# ATSAM4SD16B device description
Architecture: CORTEX-M4; Family: SAM4; Series: SAM4S
Registers are 32-bit, read-write, no defined reset value unless marked. A register's access mark holds for its fields unless they carry their own. Offsets are from the block's base; [hi:lo] are bit positions; {n}, {i} and the like mark numbered series.

## GPBR — General Purpose Backup Registers
Instances: GPBR 0x400E1490
{0x0+4i} SYS_GPBR{i} (i=0..7) — General Purpose Backup Register {i}
  [31:0] GPBR_VALUE — Value of GPBR x

## MATRIX — AHB Bus Matrix
Instances: MATRIX 0x400E0200
{0x0+4i} MATRIX_MCFG{i} (i=0..3) — Master Configuration Register {i}
  [2:0] ULBT — Undefined Length Burst Type
    0=INFINITE (No predicted end of burst is generated and therefore INCR bursts coming from this master cannot be broken.); 1=SINGLE (The undefined length burst is treated as a succession of single access allowing rearbitration at each beat of the INCR burst.); 2=FOUR_BEAT (The undefined length burst is split into a 4-beat bursts allowing rearbitration at each 4-beat burst end.); 3=EIGHT_BEAT (The undefined length burst is split into 8-beat bursts allowing rearbitration at each 8-beat burst end.); 4=SIXTEEN_BEAT (The undefined length burst is split into 16-beat bursts allowing rearbitration at each 16-beat burst end.)
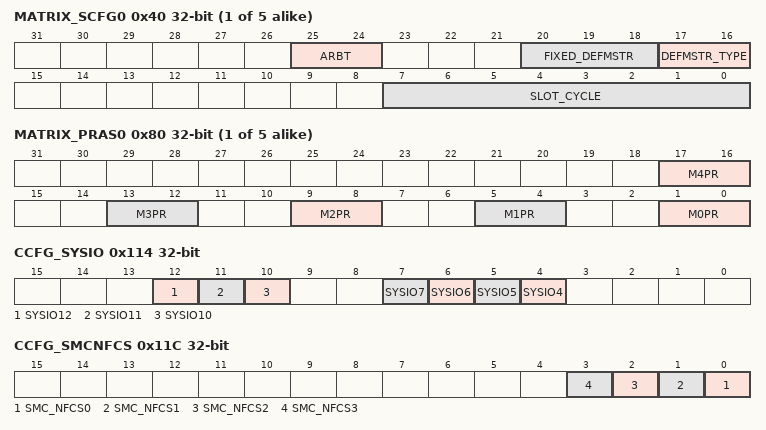
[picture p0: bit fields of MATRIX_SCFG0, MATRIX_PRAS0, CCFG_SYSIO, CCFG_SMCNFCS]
{0x40+4i} MATRIX_SCFG{i} (i=0..4) — Slave Configuration Register {i}
  [25:24] ARBT — Arbitration Type
    0=ROUND_ROBIN (Round-robin arbitration); 1=FIXED_PRIORITY (Fixed priority arbitration)
  [20:18] FIXED_DEFMSTR — Fixed Default Master
  [17:16] DEFMSTR_TYPE — Default Master Type
    0=NO_DEFAULT (At the end of current slave access, if no other master request is pending, the slave is disconnected from all masters.This results in having a one cycle latency for the first access of a burst transfer or for a single access.); 1=LAST (At the end of current slave access, if no other master request is pending, the slave stays connected to the last master having accessed it.This results in not having the one cycle latency when the last master tries to access the slave again.); 2=FIXED (At the end of the current slave access, if no other master request is pending, the slave connects to the fixed master the number that has been written in the FIXED_DEFMSTR field.This results in not having the one cycle latency when the fixed master tries to access the slave again.)
  [7:0] SLOT_CYCLE — Maximum Number of Allowed Cycles for a Burst
{0x80+8i} MATRIX_PRAS{i} (i=0..4) — Priority Register A for Slave {i}
  [4n+1:4n] M{n}PR (n=0..4) — Master {n} Priority
0x114 CCFG_SYSIO — System I/O Configuration register
  [12] SYSIO12 — PB12 or ERASE Assignment
  [11] SYSIO11 — PB11 or DDP Assignment
  [10] SYSIO10 — PB10 or DDM Assignment
  [7] SYSIO7 — PB7 or TCK/SWCLK Assignment
  [6] SYSIO6 — PB6 or TMS/SWDIO Assignment
  [5] SYSIO5 — PB5 or TDO/TRACESWO Assignment
  [4] SYSIO4 — PB4 or TDI Assignment
0x11C CCFG_SMCNFCS — SMC Chip Select NAND Flash Assignment Register
  [n] SMC_NFCS{n} (n=0..3) — SMC NAND Flash Chip Select {n} Assignment
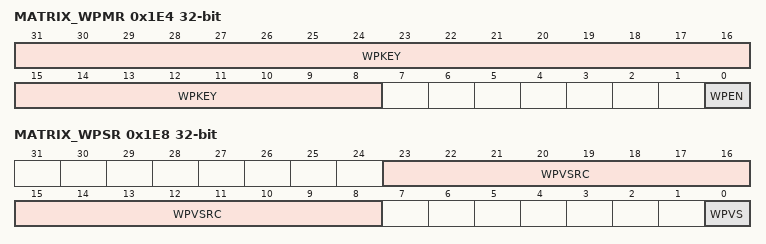
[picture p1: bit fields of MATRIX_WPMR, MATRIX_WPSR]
0x1E4 MATRIX_WPMR — Write Protection Mode Register
  [31:8] WPKEY — Write Protect Key
    0x4D4154=PASSWD (Writing any other value in this field aborts the write operation of the WPEN bit. Always reads as 0.)
  [0] WPEN — Write Protection Enable
0x1E8 MATRIX_WPSR ro — Write Protection Status Register
  [23:8] WPVSRC — Write Protection Violation Source
  [0] WPVS — Write Protection Violation Status

## PDC — Peripheral DMA Controller
0x00 PERIPH_RPR — Receive Pointer Register
  [31:0] RXPTR
0x04 PERIPH_RCR — Receive Counter Register
  [15:0] RXCTR
0x08 PERIPH_TPR — Transmit Pointer Register
  [31:0] TXPTR — Transmit Counter Register
0x0C PERIPH_TCR — Transmit Counter Register
  [15:0] TXCTR
0x10 PERIPH_RNPR — Receive Next Pointer Register
  [31:0] RXNPTR — Receive Next Pointer
0x14 PERIPH_RNCR — Receive Next Counter Register
  [15:0] RXNCTR — Receive Next Counter
0x18 PERIPH_TNPR — Transmit Next Pointer Register
  [31:0] TXNPTR — Transmit Next Pointer
0x1C PERIPH_TNCR — Transmit Next Counter Register
  [15:0] TXNCTR — Transmit Counter Next
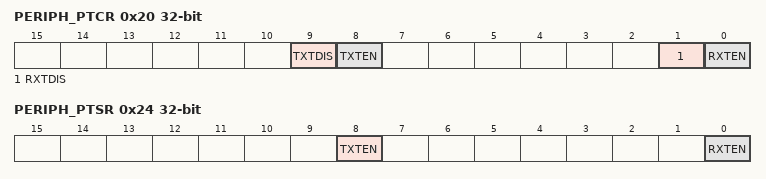
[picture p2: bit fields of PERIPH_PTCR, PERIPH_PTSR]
0x20 PERIPH_PTCR wo — Transfer Control Register
  [9] TXTDIS — Transmitter Transfer Disable
  [8] TXTEN — Transmitter Transfer Enable
  [1] RXTDIS — Receiver Transfer Disable
  [0] RXTEN — Receiver Transfer Enable
0x24 PERIPH_PTSR ro — Transfer Status Register
  [8] TXTEN — Transmitter Transfer Enable
  [0] RXTEN — Receiver Transfer Enable
